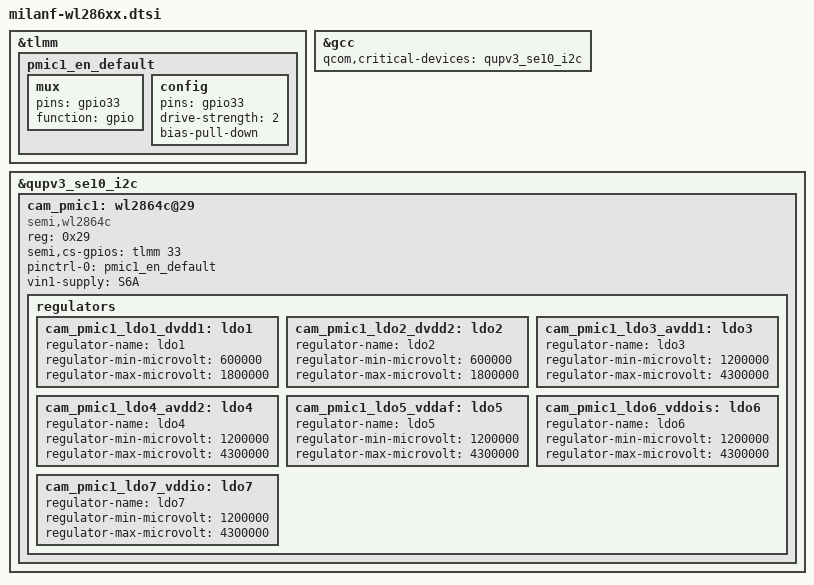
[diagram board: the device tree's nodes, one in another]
&tlmm{
	pmic1_en_default: pmic1_en_default {
		mux {
			pins = "gpio33";
			function = "gpio";
		};
		config {
			pins = "gpio33";
			drive-strength = <2>;
			bias-pull-down;
		};
	};
};

&gcc {
	qcom,critical-devices = <&qupv3_se10_i2c>;
};

&qupv3_se10_i2c {
	status = "ok";

	cam_pmic1: wl2864c@29{
		compatible = "semi,wl2864c";
		reg = <0x29>;
		semi,cs-gpios = <&tlmm 33 0>;
		pinctrl-names = "default";
		pinctrl-0 = <&pmic1_en_default>;
		vin1-supply = <&S6A>;

		regulators {
			cam_pmic1_ldo1_dvdd1: ldo1 {
				regulator-name = "ldo1";
				regulator-min-microvolt = <600000>;
				regulator-max-microvolt = <1800000>;
			};

			cam_pmic1_ldo2_dvdd2: ldo2 {
				regulator-name = "ldo2";
				regulator-min-microvolt = <600000>;
				regulator-max-microvolt = <1800000>;
			};

			cam_pmic1_ldo3_avdd1: ldo3 {
				regulator-name = "ldo3";
				regulator-min-microvolt = <1200000>;
				regulator-max-microvolt = <4300000>;
			};

			cam_pmic1_ldo4_avdd2: ldo4 {
				regulator-name = "ldo4";
				regulator-min-microvolt = <1200000>;
				regulator-max-microvolt = <4300000>;
			};

			cam_pmic1_ldo5_vddaf: ldo5 {
				regulator-name = "ldo5";
				regulator-min-microvolt = <1200000>;
				regulator-max-microvolt = <4300000>;
			};

			cam_pmic1_ldo6_vddois: ldo6 {
				regulator-name = "ldo6";
				regulator-min-microvolt = <1200000>;
				regulator-max-microvolt = <4300000>;
			};

			cam_pmic1_ldo7_vddio: ldo7 {
				regulator-name = "ldo7";
				regulator-min-microvolt = <1200000>;
				regulator-max-microvolt = <4300000>;
			};
		};
	};
};
